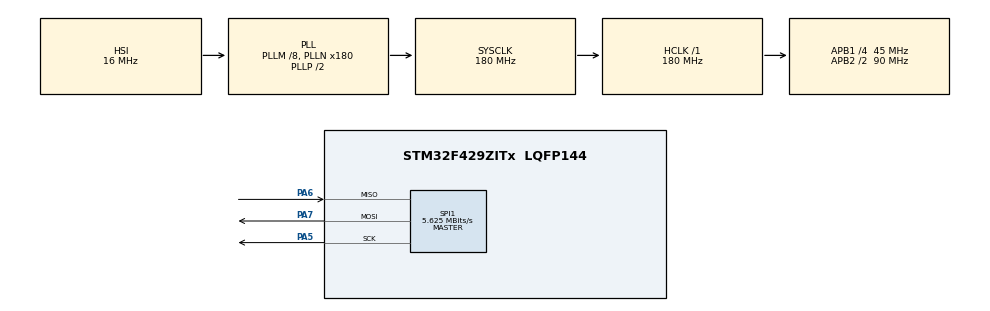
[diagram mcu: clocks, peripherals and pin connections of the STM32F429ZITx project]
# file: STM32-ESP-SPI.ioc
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Mcu.Family=STM32F4
Mcu.Name=STM32F429ZITx
Mcu.Package=LQFP144
NVIC.PriorityGroup=NVIC_PRIORITYGROUP_4
PA5.Mode=Full_Duplex_Master
PA5.Signal=SPI1_SCK
PA6.Mode=Full_Duplex_Master
PA6.Signal=SPI1_MISO
PA7.Mode=Full_Duplex_Master
PA7.Signal=SPI1_MOSI
ProjectManager.HeapSize=0x200
ProjectManager.StackSize=0x400
ProjectManager.TargetToolchain=Makefile
RCC.48MHZClocksFreq_Value=51428571.428571425
RCC.AHBFreq_Value=180000000
RCC.APB1CLKDivider=RCC_HCLK_DIV4
RCC.APB1Freq_Value=45000000
RCC.APB1TimFreq_Value=90000000
RCC.APB2CLKDivider=RCC_HCLK_DIV2
RCC.APB2Freq_Value=90000000
RCC.APB2TimFreq_Value=180000000
RCC.CortexFreq_Value=180000000
RCC.HCLKFreq_Value=180000000
RCC.HSE_VALUE=8000000
RCC.HSI_VALUE=16000000
RCC.PLLM=8
RCC.PLLMUL=RCC_PLL_MUL9
RCC.PLLN=180
RCC.PLLQ=7
RCC.PRESCALERUSB=RCC_USBCLKSOURCE_PLL_DIV1_5
RCC.SYSCLKFreq_VALUE=180000000
RCC.SYSCLKSource=RCC_SYSCLKSOURCE_PLLCLK
RCC.SYSCLKSourceVirtual=RCC_SYSCLKSOURCE_PLLCLK
RCC.USBFreq_Value=48000000
RCC.VCOOutputFreq_Value=360000000
SPI1.BaudRatePrescaler=SPI_BAUDRATEPRESCALER_16
SPI1.CalculateBaudRate=5.625 MBits/s
SPI1.Direction=SPI_DIRECTION_2LINES
SPI1.Mode=SPI_MODE_MASTER
SPI1.VirtualType=VM_MASTER
board=NUCLEO-F429ZI

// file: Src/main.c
/* USER CODE BEGIN Header */
/**
  ******************************************************************************
  * @file           : main.c
  * @brief          : Main program body
  ******************************************************************************
  * @attention
  *
  * <h2><center>&copy; Copyright (c) 2019 STMicroelectronics.
  * All rights reserved.</center></h2>
  *
  * This software component is licensed by ST under BSD 3-Clause license,
  * the "License"; You may not use this file except in compliance with the
  * License. You may obtain a copy of the License at:
  *                        opensource.org/licenses/BSD-3-Clause
  *
  ******************************************************************************
  */
/* USER CODE END Header */

#include "main.h"

SPI_HandleTypeDef hspi1;

void SystemClock_Config(void);
static void MX_GPIO_Init(void);
static void MX_SPI1_Init(void);

int main(void)
{

  /* MCU Configuration--------------------------------------------------------*/

  /* Reset of all peripherals, Initializes the Flash interface and the Systick. */
  HAL_Init();

  /* Configure the system clock */
  SystemClock_Config();

  /* Initialize all configured peripherals */
  MX_GPIO_Init();
  MX_SPI1_Init();
  /* USER CODE BEGIN 2 */

  uint8_t spi_send_MOSI_cmd[2]={0x02, 0x00};
  const uint16_t spi_cmd_size = 2;
  uint8_t data_MISO_with_cmd[32] = "Hello Slave";
  uint8_t data_MISO_1[32] = "Facbabcabc0123456789FabcabcabcFF";
  uint8_t data_MISO_2[32] = {
      0x01,0x02,0x03,0x04,0x05,0x06,0x07,0x08,0x09,0x10,
      0x11,0x22,0x23,0x14,0x15,0x16,0x17,0x18,0x19,0x20,
      0x21,0x22,0x23,0x24,0x25,0x26,0x27,0x28,0xFF,0xFF,
      0x77,0xFF
  };
  /* USER CODE END 2 */

  /* Infinite loop */
  /* USER CODE BEGIN WHILE */
  while (1)
  {
      /*HAL_SPI_Transmit(&hspi1, data_MISO_1, 32, HAL_MAX_DELAY);*/
      /*HAL_Delay(500);*/
      HAL_GPIO_WritePin(GPIOC, GPIO_PIN_0, GPIO_PIN_SET);
      HAL_SPI_Transmit(&hspi1, spi_send_MOSI_cmd, spi_cmd_size, HAL_MAX_DELAY);
      HAL_SPI_Transmit(&hspi1, data_MISO_1, 32, HAL_MAX_DELAY);
      HAL_Delay(10);
      HAL_SPI_Transmit(&hspi1, spi_send_MOSI_cmd, spi_cmd_size, HAL_MAX_DELAY);
      HAL_SPI_Transmit(&hspi1, data_MISO_2, 32, HAL_MAX_DELAY);
      HAL_Delay(10);
      HAL_SPI_Transmit(&hspi1, spi_send_MOSI_cmd, spi_cmd_size, HAL_MAX_DELAY);
      HAL_SPI_Transmit(&hspi1, data_MISO_with_cmd, 32, HAL_MAX_DELAY);
      HAL_Delay(10);
      HAL_GPIO_WritePin(GPIOC, GPIO_PIN_0, GPIO_PIN_RESET);
      HAL_Delay(50);
    /* USER CODE END WHILE */

  }
}

void SystemClock_Config(void)
{
  RCC_OscInitTypeDef RCC_OscInitStruct = {0};
  RCC_ClkInitTypeDef RCC_ClkInitStruct = {0};

  /** Configure the main internal regulator output voltage
  */
  __HAL_RCC_PWR_CLK_ENABLE();
  __HAL_PWR_VOLTAGESCALING_CONFIG(PWR_REGULATOR_VOLTAGE_SCALE1);
  /** Initializes the CPU, AHB and APB busses clocks
  */
  RCC_OscInitStruct.OscillatorType = RCC_OSCILLATORTYPE_HSI;
  RCC_OscInitStruct.HSIState = RCC_HSI_ON;
  RCC_OscInitStruct.HSICalibrationValue = RCC_HSICALIBRATION_DEFAULT;
  RCC_OscInitStruct.PLL.PLLState = RCC_PLL_ON;
  RCC_OscInitStruct.PLL.PLLSource = RCC_PLLSOURCE_HSI;
  RCC_OscInitStruct.PLL.PLLM = 8;
  RCC_OscInitStruct.PLL.PLLN = 180;
  RCC_OscInitStruct.PLL.PLLP = RCC_PLLP_DIV2;
  RCC_OscInitStruct.PLL.PLLQ = 7;
  if (HAL_RCC_OscConfig(&RCC_OscInitStruct) != HAL_OK)
  {
    Error_Handler();
  }
  /** Activate the Over-Drive mode
  */
  if (HAL_PWREx_EnableOverDrive() != HAL_OK)
  {
    Error_Handler();
  }
  /** Initializes the CPU, AHB and APB busses clocks
  */
  RCC_ClkInitStruct.ClockType = RCC_CLOCKTYPE_HCLK|RCC_CLOCKTYPE_SYSCLK
                              |RCC_CLOCKTYPE_PCLK1|RCC_CLOCKTYPE_PCLK2;
  RCC_ClkInitStruct.SYSCLKSource = RCC_SYSCLKSOURCE_PLLCLK;
  RCC_ClkInitStruct.AHBCLKDivider = RCC_SYSCLK_DIV1;
  RCC_ClkInitStruct.APB1CLKDivider = RCC_HCLK_DIV4;
  RCC_ClkInitStruct.APB2CLKDivider = RCC_HCLK_DIV2;

  if (HAL_RCC_ClockConfig(&RCC_ClkInitStruct, FLASH_LATENCY_5) != HAL_OK)
  {
    Error_Handler();
  }
}

static void MX_SPI1_Init(void)
{

  /* SPI1 parameter configuration*/
  hspi1.Instance = SPI1;
  hspi1.Init.Mode = SPI_MODE_MASTER;
  hspi1.Init.Direction = SPI_DIRECTION_2LINES;
  hspi1.Init.DataSize = SPI_DATASIZE_8BIT;
  hspi1.Init.CLKPolarity = SPI_POLARITY_LOW;
  hspi1.Init.CLKPhase = SPI_PHASE_1EDGE;
  hspi1.Init.NSS = SPI_NSS_SOFT;
  hspi1.Init.BaudRatePrescaler = SPI_BAUDRATEPRESCALER_16;
  hspi1.Init.FirstBit = SPI_FIRSTBIT_MSB;
  hspi1.Init.TIMode = SPI_TIMODE_DISABLE;
  hspi1.Init.CRCCalculation = SPI_CRCCALCULATION_DISABLE;
  hspi1.Init.CRCPolynomial = 10;
  if (HAL_SPI_Init(&hspi1) != HAL_OK)
  {
    Error_Handler();
  }

}

static void MX_GPIO_Init(void)
{

  /* GPIO Ports Clock Enable */
  __HAL_RCC_GPIOA_CLK_ENABLE();

}

void Error_Handler(void)
{
}

/************************ (C) COPYRIGHT STMicroelectronics *****END OF FILE****/
